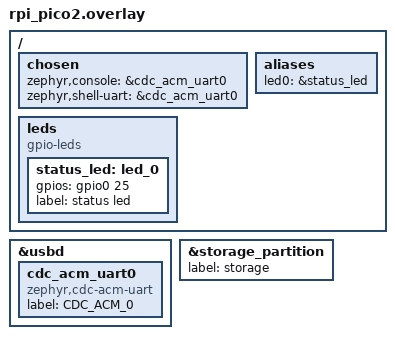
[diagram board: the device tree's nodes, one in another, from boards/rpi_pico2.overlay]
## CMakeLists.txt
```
# file: CMakeLists.txt | zephyr app build | rp2350 usb-c shell os
cmake_minimum_required(VERSION 3.20.0)
find_package(Zephyr REQUIRED HINTS $ENV{ZEPHYR_BASE})
project(rp2350_os)

target_sources(app PRIVATE src/main.c)
```

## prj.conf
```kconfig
# file: prj.conf | zephyr kernel config | rp2350 full os profile

# --- threading / scheduler ---
CONFIG_MULTITHREADING=y
CONFIG_NUM_COOP_PRIORITIES=16
CONFIG_NUM_PREEMPT_PRIORITIES=16
CONFIG_MAIN_STACK_SIZE=2048
CONFIG_SYSTEM_WORKQUEUE_STACK_SIZE=2048

# --- usb stack (cdc-acm) ---
CONFIG_USB_DEVICE_STACK=y
CONFIG_USB_DEVICE_PRODUCT="RP2350 Zephyr OS"
CONFIG_USB_DEVICE_VID=0x2e8a
CONFIG_USB_DEVICE_PID=0x000a
CONFIG_USB_CDC_ACM=y

# --- console over usb ---
CONFIG_SERIAL=y
CONFIG_UART_LINE_CTRL=y
CONFIG_UART_CONSOLE=y
CONFIG_CONSOLE=y

# --- interactive shell ("os" feel: ls/ps/kernel stats/etc) ---
CONFIG_SHELL=y
CONFIG_SHELL_BACKEND_SERIAL=y
CONFIG_KERNEL_SHELL=y
CONFIG_DEVICE_SHELL=y
CONFIG_SHELL_STACK_SIZE=4096

# --- filesystem on internal flash (littlefs) ---

# --- logging subsystem ---
CONFIG_LOG=y
CONFIG_LOG_MODE_DEFERRED=y

# --- gpio for onboard led / status ---
CONFIG_GPIO=y

# --- stdc / newlib for shell string ops ---
CONFIG_PICOLIBC=y
CONFIG_HEAP_MEM_POOL_SIZE=16384
```

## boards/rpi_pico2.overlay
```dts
/* file: rpi_pico2.overlay | devicetree overlay | waveshare rp2350 usb-c board */

/ {
	chosen {
		zephyr,console = &cdc_acm_uart0;
		zephyr,shell-uart = &cdc_acm_uart0;
	};

	aliases {
		led0 = &status_led;
	};

	leds {
		compatible = "gpio-leds";
		status_led: led_0 {
			/* FILL: onboard LED GPIO pin — waveshare rp2350 usb-c schematic,
			   most waveshare rp2350 boards use GP25, verify against your
			   board's pinout PDF before flashing */
			gpios = <&gpio0 25 GPIO_ACTIVE_HIGH>;
			label = "status led";
		};
	};
};

&usbd {
	status = "okay";
	cdc_acm_uart0: cdc_acm_uart0 {
		compatible = "zephyr,cdc-acm-uart";
		label = "CDC_ACM_0";
	};
};

/* rpi_pico2 board base .dts already defines code_partition (slot0_partition)
 * and a storage_partition — we only add/relabel storage_partition to the
 * node name littlefs expects, no need to redeclare the whole partitions
 * table and no risk of duplicate labels */
&storage_partition {
	label = "storage";
};
```

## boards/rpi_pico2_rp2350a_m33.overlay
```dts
/* file: rpi_pico2_rp2350a_m33.overlay | devicetree overlay | waveshare rp2350 usb-c board */

/ {
	chosen {
		zephyr,console = &cdc_acm_uart0;
		zephyr,shell-uart = &cdc_acm_uart0;
	};

	aliases {
		led0 = &status_led;
	};

	leds {
		compatible = "gpio-leds";
		status_led: led_0 {
			gpios = <&gpio0 25 GPIO_ACTIVE_HIGH>;
			label = "status led";
		};
	};
};

&usbd {
	status = "okay";
	cdc_acm_uart0: cdc_acm_uart0 {
		compatible = "zephyr,cdc-acm-uart";
		label = "CDC_ACM_0";
	};
};
```

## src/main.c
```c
/* file: main.c | runtime: zephyr rtos | target: waveshare rp2350 usb-c (rpi_pico2 board) */

#include <zephyr/kernel.h>
#include <zephyr/device.h>
#include <zephyr/drivers/gpio.h>
#include <zephyr/drivers/uart.h>
#include <zephyr/usb/usb_device.h>
#include <zephyr/shell/shell.h>
#include <zephyr/logging/log.h>

LOG_MODULE_REGISTER(os_main, LOG_LEVEL_INF);

static const struct gpio_dt_spec status_led = GPIO_DT_SPEC_GET_OR(DT_ALIAS(led0), gpios, {0});

static void heartbeat_thread(void *a, void *b, void *c)
{
	ARG_UNUSED(a); ARG_UNUSED(b); ARG_UNUSED(c);

	bool led_ready = gpio_is_ready_dt(&status_led);
	if (led_ready) {
		gpio_pin_configure_dt(&status_led, GPIO_OUTPUT_ACTIVE);
	} else {
		LOG_WRN("status led not ready — check boards/rpi_pico2_rp2350a_m33.overlay pin");
	}

	while (1) {
		if (led_ready) {
			gpio_pin_toggle_dt(&status_led);
		}
		k_msleep(500);
	}
}

K_THREAD_DEFINE(heartbeat_tid, 512, heartbeat_thread, NULL, NULL, NULL, 7, 0, 0);

static int cmd_uname(const struct shell *sh, size_t argc, char **argv)
{
	ARG_UNUSED(argc); ARG_UNUSED(argv);
	shell_print(sh, "Zephyr RTOS | rp2350 (cortex-m33) | waveshare rp2350 usb-c");
	return 0;
}
SHELL_CMD_REGISTER(uname, NULL, "print os/kernel identity", cmd_uname);

/* heap/thread stats available via stock shell: "kernel stacks", "kernel threads" */

int main(void)
{
	LOG_INF("boot: zephyr os on rp2350 (waveshare usb-c)");

	int usb_rc = usb_enable(NULL);
	if (usb_rc != 0 && usb_rc != -EALREADY) {
		LOG_ERR("usb_enable failed: %d", usb_rc);
	}

	LOG_INF("ready — connect via usb-c, open serial terminal, press enter for shell");
	return 0;
}
```
